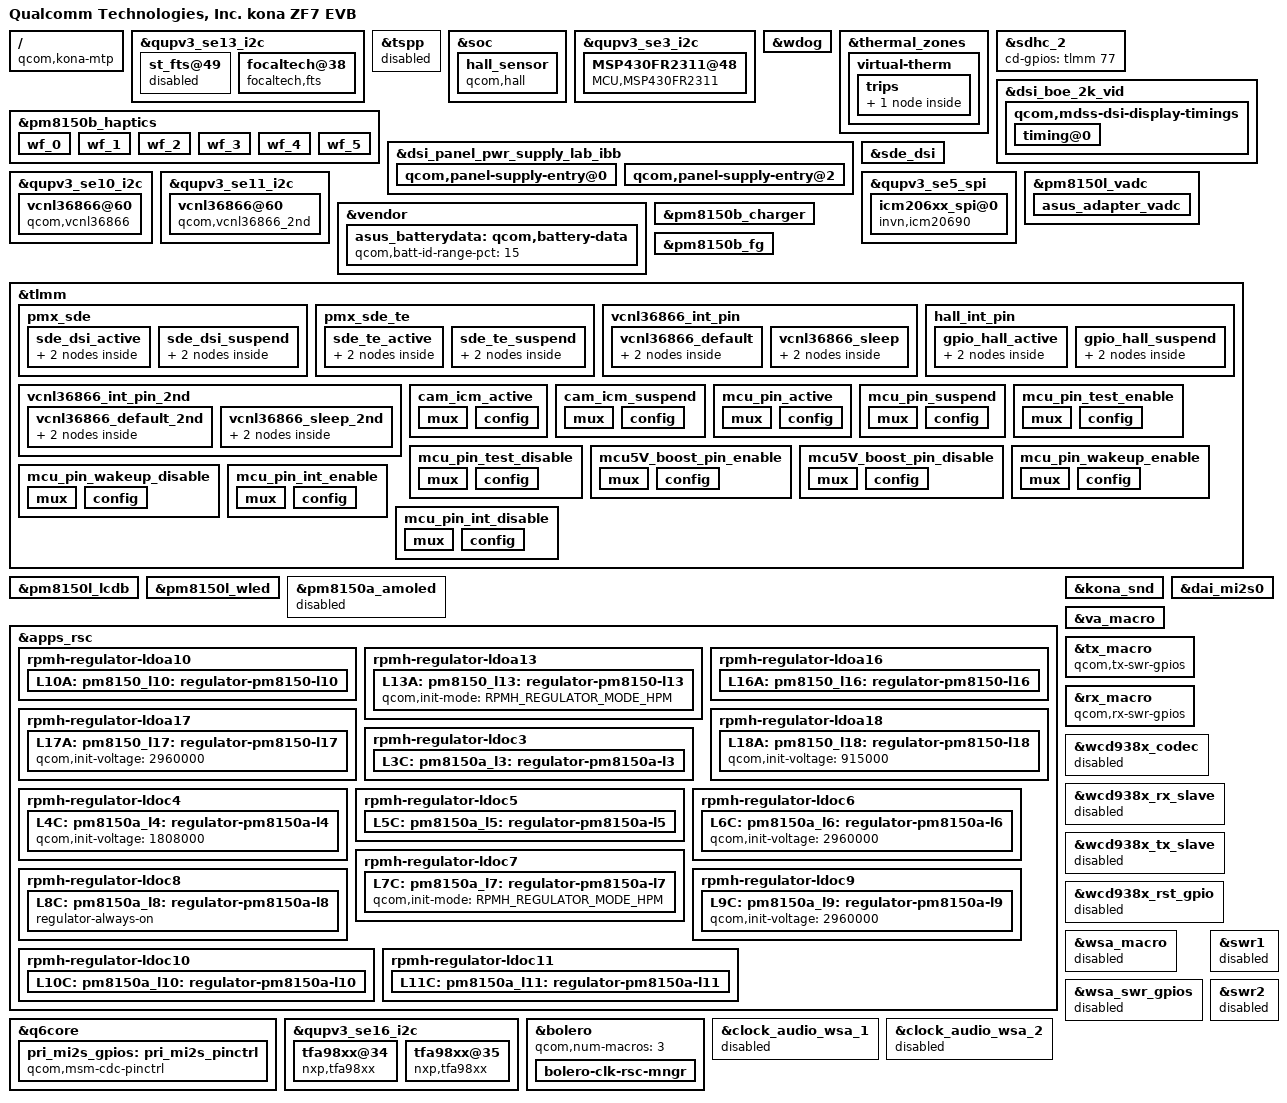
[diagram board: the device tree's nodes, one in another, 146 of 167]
/dts-v1/;
/plugin/;

#include <dt-bindings/clock/qcom,gcc-kona.h>
#include <dt-bindings/clock/qcom,camcc-kona.h>
#include <dt-bindings/clock/qcom,rpmh.h>
#include <dt-bindings/interrupt-controller/arm-gic.h>
#include <dt-bindings/regulator/qcom,rpmh-regulator-levels.h>

#include "kona-mtp.dtsi"
 #include "camera/zs670ks-evb-camera-sensor-mtp.dtsi"
// ZS670KS_Display_Lotta_Lu +++++++++ 
#include "dsi-panel-boe-2k-video.dtsi"
//ZS670KS_Display_Lotta_Lu --------

// ZS670KS_fingerprint;asus_bsp++
#include "zs670ks-goodix-fp.dtsi"
//ZS670KS_fingerprint;asus_bsp--

/ {
	model = "Qualcomm Technologies, Inc. kona ZF7 EVB";
	compatible = "qcom,kona-mtp", "qcom,kona", "qcom,mtp";
	qcom,board-id = <30 0>;
};




/*    ====================================
 *    overlay for kona-v2.dtsi - start
 *    ====================================
 */

/*    ====================================
 *    overlay for kona-v2.dtsi - end
 *    ====================================
 */



/*    ====================================
 *    overlay for kona.dtsi - start
 *    ====================================
 */
// ZS670KS touch Yadong +++
&qupv3_se13_i2c {
	status = "ok";
	/delete-property/ qcom,i2c-touch-active;

	st_fts@49 {
		status = "disable";
	};

	focaltech@38 {
		compatible = "focaltech,fts";
		reg = <0x38>;
		interrupt-parent = <&tlmm>;
		interrupts = <68 0x2008>;
		focaltech,reset-gpio = <&tlmm 69 0x01>;
		focaltech,irq-gpio = <&tlmm 68 0x2008>;
		focaltech,max-touch-number = <10>;
		vdd-supply = <&pm8150_l14>;
		lab-supply = <&lcdb_ldo_vreg>;
		ibb-supply = <&lcdb_ncp_vreg>;
		focaltech,regulator_dvdd = "vdd";
		focaltech,regulator_lab = "lab";
		focaltech,regulator_ibb = "ibb";
		focaltech,display-coords = <0 0 1080 2340>;
	};
};

&tspp {
	status = "disable";
};
// ZS670KS touch Yadong ---

//ZS670KS_HALL_sensor_Timo_Xu ++++++++++
&soc {
	
	hall_sensor {
		compatible = "qcom,hall";
		pinctrl-names = "hall_gpio_high","hall_gpio_low";
		pinctrl-0 = <&gpio_hall_active>;
		pinctrl-1 = <&gpio_hall_suspend>;			
		qcom,hall-gpio = <&tlmm 121 0x0>;
	};
};
//ZS670KS_HALL_sensor_Timo_Xu --------

//ZS670KS Camera moto, start.
&qupv3_se3_i2c {
        status = "ok";
        MSP430FR2311@48 {
			compatible = "MCU,MSP430FR2311";
			reg = <0x48>;
			vcc_s4a_1p8-supply = <&pm8150_s4>;
			vcc_l10a_3p3-supply = <&pm8150_l10>;
			pinctrl-names = "mcu_active", "mcu_suspend";
			pinctrl-0 = <&mcu_pin_active &mcu_pin_test_enable &mcu5V_boost_pin_enable &mcu_pin_wakeup_enable &mcu_pin_int_enable>;
			pinctrl-1 = <&mcu_pin_suspend &mcu_pin_test_disable &mcu5V_boost_pin_disable &mcu_pin_wakeup_disable &mcu_pin_int_disable>;
			gpios = <&tlmm 112 0>,<&tlmm 113 0>, <&tlmm 62 0>, <&tlmm 114 0> , <&tlmm 162 0>;

			MCU,mcureset-gpios = <&tlmm 112 0x00>;
			MCU,mcutest-gpios = <&tlmm 113 0x00>;
			MCU,mcu5V_boost_enable-gpios = <&tlmm 62 0x00>;
			MCU,mcuwakeup-gpios = <&tlmm 114 0x00>;
			MCU,mcuint-gpios = <&tlmm 162 0x00>;
			MCU,slave_address = <0x48>;
        };
};
//ZS670KS Camera moto, end.

//ZS670KS Watchdog ++++
&wdog {
	qcom,bark-time = <15000>;
	qcom,pet-time = <9360>;
};
//ZS670KS Watchdog ++

 /*    ====================================
 *    overlay for kona.dtsi - end
 *    ====================================
 */


/*    ====================================
 *    overlay for kona-mtp.dtsi - start
 *    ====================================
 */
 
 &thermal_zones { 	
	virtual-therm {
		polling-delay-passive = <0>;
		polling-delay = <0>;
		thermal-governor = "user_space";
		thermal-sensors = <&pm8150l_adc_tm ADC_AMUX_THM2_PU2>;
		trips {
			active-config0 {
				temperature = <125000>;
				hysteresis = <1000>;
				type = "passive";
			};
		};
	};
};
 
// ZS670KS_Haptics_Ryan_Ren +++++++++
&pm8150b_haptics {
	qcom,vmax-mv = <2420>;
	qcom,play-rate-us = <4255>;
	qcom,wf-brake-pattern = [02 02 02 02];
	wf_0 {
		/* CLICK */
		qcom,effect-id = <0>;
		qcom,wf-vmax-mv = <3596>;
		qcom,wf-pattern = [3e 3e 3e];
		qcom,wf-play-rate-us = <4255>;
		qcom,wf-brake-pattern = [02 02 00 00];
		/delete-property/ qcom,wf-repeat-count;
		/delete-property/ qcom,wf-s-repeat-count;
		/delete-property/ qcom,lra-auto-resonance-disable;
	};
	wf_1 {
		/* DOUBLE CLICK */
		qcom,effect-id = <1>;
		qcom,wf-vmax-mv = <2900>;
		qcom,wf-pattern = [7e 7e 02 02 02 02 02 02];
		qcom,wf-play-rate-us = <4166>;
		qcom,wf-repeat-count = <2>;
		qcom,wf-s-repeat-count = <1>;
		qcom,wf-brake-pattern = [02 02 00 00];
		/delete-property/ qcom,lra-auto-resonance-disable;
	}; 
	wf_2 {
		/* TICK */
		qcom,effect-id = <2>;
		qcom,wf-vmax-mv = <2900>;
		qcom,wf-pattern = [7e 7e];
		qcom,wf-play-rate-us = <4166>;
		qcom,wf-brake-pattern = [02 02 00 00];
		/delete-property/ qcom,wf-repeat-count;
		/delete-property/ qcom,wf-s-repeat-count;
		/delete-property/ qcom,lra-auto-resonance-disable;
	};
	wf_3 {
		/* THUD */
		qcom,effect-id = <3>;
		qcom,wf-vmax-mv = <2900>;
		qcom,wf-pattern = [7e 7e 7e];
		qcom,wf-play-rate-us = <4166>;
		qcom,wf-brake-pattern = [02 02 00 00];
		/delete-property/ qcom,wf-repeat-count;
		/delete-property/ qcom,wf-s-repeat-count;
		/delete-property/ qcom,lra-auto-resonance-disable;
	};
	wf_4 {
		/* POP */
		qcom,effect-id = <4>;
		qcom,wf-vmax-mv = <2900>;
		qcom,wf-pattern = [7e 7e];
		qcom,wf-play-rate-us = <4166>;
		qcom,wf-brake-pattern = [02 02 00 00];
		/delete-property/ qcom,wf-repeat-count;
		/delete-property/ qcom,wf-s-repeat-count;
		/delete-property/ qcom,lra-auto-resonance-disable;
	};
	wf_5 {
		/* HEAVY CLICK */
		qcom,effect-id = <5>;
		qcom,wf-vmax-mv = <2900>;
		qcom,wf-pattern = [7e 7e 7e];
		qcom,wf-play-rate-us = <4166>;
		qcom,wf-brake-pattern = [02 02 00 00];
		/delete-property/ qcom,wf-repeat-count;
		/delete-property/ qcom,wf-s-repeat-count;
		/delete-property/ qcom,lra-auto-resonance-disable;
	};
}; 
// ZS670KS_Haptics_Ryan_Ren ---------



//ZS670KS SDCARD Bevis ++++++++++++
&sdhc_2 {
	cd-gpios = <&tlmm 77 GPIO_ACTIVE_HIGH>;
	status = "ok";
};
//ZS670KS SDCARD Bevis ---------


// ZS670KS_Display_Lotta_Lu +++++++++ 
&dsi_panel_pwr_supply_lab_ibb {

	qcom,panel-supply-entry@0 {
		/delete-property/ qcom,supply-post-on-sleep;
	};

	qcom,panel-supply-entry@2 {
		/delete-property/ qcom,supply-post-on-sleep;
	};
};


&dsi_boe_2k_vid {

	qcom,panel-supply-entries = <&dsi_panel_pwr_supply_lab_ibb>;
	qcom,mdss-dsi-bl-pmic-control-type = "bl_ctrl_dcs";
	qcom,mdss-dsi-bl-min-level = <1>;
	qcom,mdss-dsi-bl-max-level = <4095>;
	qcom,mdss-dsi-mode-sel-gpio-state = "single_port";
	qcom,platform-te-gpio = <&tlmm 71 0>;
	qcom,platform-reset-gpio = <&tlmm 75 0>;

	qcom,mdss-dsi-display-timings {
		timing@0 {
			qcom,mdss-dsi-panel-phy-timings = [00 22 09 09 25 24 09
				09 06 02 04 00 1C 19];
			qcom,display-topology = <1 0 1>;
			qcom,default-topology-index = <0>;
		};
	};
};

&sde_dsi {
	/delete-property/ vdd-supply;
	/delete-property/ avdd-supply;

	lab-supply = <&lcdb_ldo_vreg>;
	ibb-supply = <&lcdb_ncp_vreg>;

	qcom,dsi-default-panel = <&dsi_boe_2k_vid>;
};
//ZS670KS_Display_Lotta_Lu --------

// ASUS_BSP +++ ClayWang vcnl36866 
&qupv3_se10_i2c {
        status = "ok";
            vcnl36866@60 {
			compatible = "qcom,vcnl36866";
			reg = <0x60>;
			pinctrl-names = "alsps_gpio_high","alsps_gpio_low";
			pinctrl-0 = <&vcnl36866_default>;
			pinctrl-1 = <&vcnl36866_sleep>;
			qcom,alsps-gpio = <&tlmm 126 0x0>;
			vcc_psensor-supply = <&pm8150a_l10>;
		};
};

&qupv3_se11_i2c {
        status = "ok";
            vcnl36866@60 {
			compatible = "qcom,vcnl36866_2nd";
			reg = <0x60>;
			pinctrl-names = "alsps_gpio_high_2nd","alsps_gpio_low_2nd";
			pinctrl-0 = <&vcnl36866_default_2nd>;
			pinctrl-1 = <&vcnl36866_sleep_2nd>;
			qcom,alsps-gpio_2nd = <&tlmm 67 0x0>;
			vcc_psensor-supply = <&pm8150a_l10>;
		};
};
// ASUS_BSP --- ClayWang vcnl36866

/* ASUS_BSP +++ icm20690 */
&qupv3_se5_spi {
	status = "ok";
        icm206xx_spi@0 {
                spi-max-frequency = <10000000>;
                compatible = "invn,icm20690";
                reg = <0x0>;
                invn,gpio-int = <&tlmm 124 1>;
                invn,use-interrupt;
                invn,place = "Portrait Down Back Side";
                icm206xx-supply = <&pm8150a_l1>;
                pinctrl-names = "cam_default", "cam_suspend";
                pinctrl-0 = <&cam_icm_active>;
                pinctrl-1 = <&cam_icm_suspend>;
        };
};
/* ASUS_BSP --- icm20690 */

/*    ====================================
 *    overlay for kona-mtp.dtsi - end
 *    ====================================
 */



// ASUS_BSP Fuel guage/Charger dtsi overlay +++
&vendor {
	asus_batterydata: qcom,battery-data {
		qcom,batt-id-range-pct = <15>;
		#include "fg-gen4-batterydata-mlp466076-3250mah.dtsi"
	};
};

&pm8150l_vadc {
	asus_adapter_vadc {
		reg = <ADC_GPIO4>;
		label = "asus_adapter_vadc";
		qcom,hw-settle-time = <200>;
		qcom,pre-scaling = <1 1>;
	};
};

&pm8150b_charger {
	io-channels = <&pm8150b_vadc ADC_MID_CHG_DIV6>,
		      <&pm8150b_vadc ADC_USB_IN_I>,
		      <&pm8150b_vadc ADC_SBUx>,
		      <&pm8150b_vadc ADC_VPH_PWR>,
		      <&pm8150b_vadc ADC_AMUX_THM3_PU2>,
		      <&pm8150b_vadc ADC_CHG_TEMP>,
		      <&pm8150l_vadc ADC_GPIO4>;
	io-channel-names = "mid_voltage",
			   "usb_in_current",
			   "sbux_res",
			   "vph_voltage",
			   "conn_temp",
			   "chg_temp",
			   "asus_adapter_vadc";
	ADCPWREN_PMI_GP1-gpio82 = <&pm8150b_gpios 3 0x0>; //EVB use PM8150B GPIO3, SR use SM8250 GPIO82
	ADC_SW_EN-gpio98 = <&tlmm 98 0x0>;
	qcom,battery-data = <&asus_batterydata>;
};

&pm8150b_fg {
	qcom,battery-data = <&asus_batterydata>;
	qcom,fg-cutoff-voltage = <3400>;
	qcom,fg-empty-voltage = <2650>;
	qcom,fg-cutoff-current = <100>;
	qcom,fg-force-load-profile;
};
// ASUS_BSP Fuel guage/Charger dtsi overlay ---

/*    ====================================
 *    overlay for kona-pinctrl.dtsi - start
 *    ====================================
 */
 
&tlmm{
// ZS670KS_Display_Lotta_Lu +++++++++ 

		pmx_sde: pmx_sde {
		
			sde_dsi_active: sde_dsi_active {
				mux {
					pins = "gpio75";
					function = "gpio";
				};

				config {
					pins = "gpio75";
					drive-strength = <8>;   /* 8 mA */
					bias-disable = <0>;   /* no pull */
				};
			};

			sde_dsi_suspend: sde_dsi_suspend {
				mux {
					pins = "gpio75";
					function = "gpio";
				};

				config {
					pins = "gpio75";
					drive-strength = <2>;   /* 2 mA */
					bias-pull-down;         /* PULL DOWN */
				};
			};
		};

		pmx_sde_te {
			sde_te_active: sde_te_active {
				mux {
					pins = "gpio71";
					function = "mdp_vsync";
				};

				config {
					pins = "gpio71";
					drive-strength = <2>;   /* 2 mA */
					bias-pull-down;         /* PULL DOWN */
				};
			};

			sde_te_suspend: sde_te_suspend {
				mux {
					pins = "gpio71";
					function = "mdp_vsync";
				};

				config {
					pins = "gpio71";
					drive-strength = <2>;   /* 2 mA */
					bias-pull-down;         /* PULL DOWN */
				};
			};
		};
//ZS670KS_Display_Lotta_Lu --------
		/* ASUS_BSP +++ ClayWang vcnl36866 */
		vcnl36866_int_pin {
			vcnl36866_default: vcnl36866_default {
				mux {
					pins = "gpio126";
					function = "gpio";
				};

				config {
					pins = "gpio126";
					bias-pull-up;
					drive-strength = <6>;
				};
			};

			vcnl36866_sleep: vcnl36866_sleep {
				mux {
					pins = "gpio126";
					function = "gpio";
				};

				config {
					pins = "gpio126";
					bias-pull-up;
					drive-strength = <6>;
				};
			};
		};
		vcnl36866_int_pin_2nd {
			vcnl36866_default_2nd: vcnl36866_default_2nd {
				mux {
					pins = "gpio67";
					function = "gpio";
				};

				config {
					pins = "gpio67";
					bias-pull-up;
					drive-strength = <6>;
				};
			};

			vcnl36866_sleep_2nd: vcnl36866_sleep_2nd {
				mux {
					pins = "gpio67";
					function = "gpio";
				};

				config {
					pins = "gpio67";
					bias-pull-up;
					drive-strength = <6>;
				};
			};
		};
		/* ASUS_BSP --- ClayWang vncl36866 */

//ZS670KS_HALL_sensor_Timo_Xu ++++++++
		hall_int_pin {

			gpio_hall_active: gpio_hall_active {
 				mux {
 					pins = "gpio121";
 					function = "gpio";
				};
 
 				config {
 					pins = "gpio121";
 					drive-strength = <2>;
 					bias-disable;
 				};
 			};
 			gpio_hall_suspend: gpio_hall_suspend {
 				mux {
 					pins = "gpio121";
 					function = "gpio";
 				};
 
 				config {
 					pins = "gpio121";
 					drive-strength = <2>;
 					bias-disable;
 				};
 			};
		};
//ZS670KS_HALL_sensor_Timo_Xu --------
		/* ASUS_BSP +++ icm20690 */
		cam_icm_active: cam_icm_active {
			mux {
				pins = "gpio124";
				function = "gpio";
			};

			config {
				pins = "gpio124";
				bias-pull-up;
				drive-strength = <8>;
			};
		};

		cam_icm_suspend: cam_icm_suspend {
			mux {
				pins = "gpio124";
				function = "gpio";
			};

			config {
				pins = "gpio124";
				bias-pull-down;
				drive-strength = <2>; 
			};
		};
		/* ASUS_BSP --- icm20690 */
//ZS670KS, camera moto related gpio, start.
mcu_pin_active: mcu_pin_active {
	mux {
		pins = "gpio112";
		function = "gpio";
	};

	config {
		pins = "gpio112";
		bias-pull-up; /* PULL UP */
		drive-strength = <2>; /* 2 MA */
	};
};

mcu_pin_suspend: mcu_pin_suspend {
	mux {
		pins = "gpio112";
		function = "gpio";
	};

	config {
		pins = "gpio112";
		bias-pull-up; /* PULL UP */
		drive-strength = <2>; /* 2 MA */
	};
};

mcu_pin_test_enable: mcu_pin_test_enable {
	mux {
		pins = "gpio113";
		function = "gpio";
	};

	config {
		pins = "gpio113";
		bias-pull-down; /* PULL UP */
		drive-strength = <2>; /* 2 MA */
	};
};

mcu_pin_test_disable: mcu_pin_test_disable {
	mux {
		pins = "gpio113";
		function = "gpio";
	};

	config {
		pins = "gpio113";
		bias-pull-down; /* PULL UP */
		drive-strength = <2>; /* 2 MA */
	};
};

mcu5V_boost_pin_enable: mcu5V_boost_pin_enable {
	mux {
		pins = "gpio62";
		function = "gpio";
	};

	config {
		pins = "gpio62";
		bias-pull-up; 
		drive-strength = <2>; /* 2 MA */
	};
};

mcu5V_boost_pin_disable: mcu5V_boost_pin_disable {
	mux {
		pins = "gpio62";
		function = "gpio";
	};

	config {
		pins = "gpio62";
		bias-pull-down; 
		drive-strength = <2>; /* 2 MA */
	};
};

mcu_pin_wakeup_enable: mcu_pin_wakeup_enable {
	mux {
		pins = "gpio114";
		function = "gpio";
	};

	config {
		pins = "gpio114";
		bias-pull-up; 
		drive-strength = <2>; /* 2 MA */
	};
};

mcu_pin_wakeup_disable: mcu_pin_wakeup_disable {
	mux {
		pins = "gpio114";
		function = "gpio";
	};

	config {
		pins = "gpio114";
		bias-pull-down; 
		drive-strength = <2>; /* 2 MA */
	};
};

mcu_pin_int_enable: mcu_pin_int_enable {
	mux {
		pins = "gpio162";
		function = "gpio";
	};

	config {
		pins = "gpio162";
		bias-pull-up; 
		drive-strength = <2>; /* 2 MA */
	};
};

mcu_pin_int_disable: mcu_pin_int_disable {
	mux {
		pins = "gpio162";
		function = "gpio";
	};

	config {
		pins = "gpio162";
		bias-pull-down; 
		drive-strength = <2>; /* 2 MA */
	};
};	
//ZS670KS, camera moto related gpio, end.

};

/*    ====================================
 *    overlay for kona-pinctrl.dtsi - end
 *    ====================================
 */



/*    ====================================
 *    overlay for kona-pmic-overlay.dtsi  - start
 *    ====================================
 */

// ZS670KS_Display_Lotta_Lu +++++++++ 
&pm8150l_lcdb {
	status = "ok";
};

&pm8150l_wled {
	status = "ok";
	qcom,en-cabc;
	qcom,cabc-sel = <1>;
	qcom,fs-current = <9>; //8 = 20mA, 9 = 22.5mA, max is 12, min is 0
	qcom,string-cfg= <3>;
	qcom,leds-per-string = <8>;
};

&pm8150a_amoled{
	status = "disabled";
};
//ZS670KS_Display_Lotta_Lu --------
/*    ====================================
 *    overlay for kona-pmic-overlay.dtsi - end
 *    ====================================
 */



/*    ====================================
 *    overlay for kona-regulator.dtsi - start
 *    ====================================
 */
 
// ASUS_BSP +++ ClayWang vcnl36866 
&apps_rsc {

	rpmh-regulator-ldoa10 {
			L10A: pm8150_l10: regulator-pm8150-l10 {
				regulator-max-microvolt = <3300000>;
				qcom,init-voltage = <3300000>;
			};
	};

	rpmh-regulator-ldoa13 {
		L13A: pm8150_l13: regulator-pm8150-l13 {
			qcom,init-mode = <RPMH_REGULATOR_MODE_HPM>;
		};
	};

	rpmh-regulator-ldoa16 {
		L16A: pm8150_l16: regulator-pm8150-l16 {
			regulator-min-microvolt = <2850000>;
			qcom,init-voltage = <2850000>;
		};
	};

	rpmh-regulator-ldoa17 {
		L17A: pm8150_l17: regulator-pm8150-l17 {
			qcom,init-voltage = <2960000>;
		};
	};

	rpmh-regulator-ldoa18 {
		L18A: pm8150_l18: regulator-pm8150-l18 {
			qcom,init-voltage = <915000>;
		};
	};

	rpmh-regulator-ldoc3 {
		L3C: pm8150a_l3: regulator-pm8150a-l3 {
			qcom,init-voltage = <1200000>;
			qcom,init-mode = <RPMH_REGULATOR_MODE_HPM>;
		};
	};

	rpmh-regulator-ldoc4 {
		L4C: pm8150a_l4: regulator-pm8150a-l4 {
			qcom,init-voltage = <1808000>;
		};
	};

	rpmh-regulator-ldoc5 {
		L5C: pm8150a_l5: regulator-pm8150a-l5 {
			qcom,init-voltage = <1808000>;
			qcom,init-mode = <RPMH_REGULATOR_MODE_HPM>;
		};
	};

	rpmh-regulator-ldoc6 {
		L6C: pm8150a_l6: regulator-pm8150a-l6 {
			qcom,init-voltage = <2960000>;
		};
	};

	rpmh-regulator-ldoc7 {
		L7C: pm8150a_l7: regulator-pm8150a-l7 {
			qcom,init-mode = <RPMH_REGULATOR_MODE_HPM>;
		};
	};

	rpmh-regulator-ldoc8 {
		/*
		qcom,supported-modes =
			<RPMH_REGULATOR_MODE_LPM
			 RPMH_REGULATOR_MODE_HPM>;
		*/
		L8C: pm8150a_l8: regulator-pm8150a-l8 {
			//qcom,init-mode = <RPMH_REGULATOR_MODE_HPM>;
			regulator-always-on;	/* ASUS BSP Always Enable 1.8V for I2C & Sensors */
		};
	};

	rpmh-regulator-ldoc9 {
		L9C: pm8150a_l9: regulator-pm8150a-l9 {
			qcom,init-voltage = <2960000>;
		};
	};

	rpmh-regulator-ldoc10 {
		L10C: pm8150a_l10: regulator-pm8150a-l10 {
			regulator-min-microvolt = <3000000>;
			regulator-max-microvolt = <3000000>;
			qcom,init-mode = <RPMH_REGULATOR_MODE_HPM>;
			regulator-always-on;	/* ASUS BSP Always Enable 1.8V for I2C & Sensors */
		};
	};

	rpmh-regulator-ldoc11 {
		L11C: pm8150a_l11: regulator-pm8150a-l11 {
			qcom,init-voltage = <3300000>;
			qcom,init-mode = <RPMH_REGULATOR_MODE_HPM>;
		};
	};

};
// ASUS_BSP --- ClayWang vcnl36866 

/*    ====================================
 *    overlay for kona-regulator.dtsi - end
 *    ====================================
 */
 


/*    ====================================
 *    overlay for kona-audio-overlay.dtsi - start
 *    ====================================
 */
&kona_snd {
	qcom,model = "kona-mtp-snd-card";
	qcom,msm-mi2s-master = <1>, <1>, <1>, <1>, <1>, <1>;
	qcom,wcn-bt = <1>;
	qcom,ext-disp-audio-rx = <1>;
    qcom,mi2s-audio-intf = <1>;
    qcom,pri-mi2s-gpios = <&pri_mi2s_gpios>;
	qcom,audio-routing =
		"RX_TX DEC0_INP", "TX DEC0 MUX",
		"RX_TX DEC1_INP", "TX DEC1 MUX",
		"RX_TX DEC2_INP", "TX DEC2 MUX",
		"RX_TX DEC3_INP", "TX DEC3 MUX",
		"VA_AIF1 CAP", "VA_SWR_CLK",
		"VA_AIF2 CAP", "VA_SWR_CLK",
		"VA_AIF3 CAP", "VA_SWR_CLK",
		"VA MIC BIAS", "Digital Mic0",
		"VA MIC BIAS", "Digital Mic1",
		"VA MIC BIAS", "Digital Mic2",
		"VA MIC BIAS", "Digital Mic3",
		"VA MIC BIAS", "Digital Mic4",
		"VA MIC BIAS", "Digital Mic5",
		"VA DMIC0", "VA MIC BIAS",
		"VA DMIC1", "VA MIC BIAS",
		"VA DMIC2", "VA MIC BIAS",
		"VA DMIC3", "VA MIC BIAS",
		"VA DMIC4", "VA MIC BIAS",
		"VA DMIC5", "VA MIC BIAS";
	qcom,msm-mbhc-hphl-swh;
	qcom,msm-mbhc-gnd-swh;
	qcom,cdc-dmic01-gpios = <&cdc_dmic01_gpios>;
	qcom,cdc-dmic23-gpios = <&cdc_dmic23_gpios>;
	qcom,cdc-dmic45-gpios = <&cdc_dmic45_gpios>;
	asoc-codec  = <&stub_codec>, <&bolero>, <&ext_disp_audio_codec>;
	asoc-codec-names = "msm-stub-codec.1", "bolero_codec",
			   "msm-ext-disp-audio-codec-rx";
	qcom,wsa-max-devs = <0>;
	qcom,wsa-devs;
	qcom,wsa-aux-dev-prefix;
	qcom,codec-max-aux-devs = <0>;
	qcom,codec-aux-devs;
	qcom,msm_audio_ssr_devs = <&audio_apr>, <&q6core>, <&lpi_tlmm>,
				  <&bolero>;
};

&q6core {
    pri_mi2s_gpios: pri_mi2s_pinctrl {
        compatible = "qcom,msm-cdc-pinctrl";
		pinctrl-names = "aud_active", "aud_sleep";
		pinctrl-0 = <&pri_aux_pcm_clk_active &pri_aux_pcm_din_active &pri_aux_pcm_dout_active &pri_aux_pcm_sync_active>;
		pinctrl-1 = <&pri_aux_pcm_clk_sleep &pri_aux_pcm_din_sleep &pri_aux_pcm_dout_sleep &pri_aux_pcm_sync_sleep>;
    };
};

&qupv3_se16_i2c {
       status = "ok";
	tfa98xx@34 {
		compatible = "nxp,tfa98xx";
		reg = <0x34>;
		reset-gpio = <&tlmm 72 0>;
		irq-gpio = <&tlmm 64 0>;
	};
	tfa98xx@35 {
		compatible = "nxp,tfa98xx";
		reg = <0x35>;
		reset-gpio = <&tlmm 73 0>;
		irq-gpio = <&tlmm 63 0>;
        };
};

&dai_mi2s0 {
    qcom,msm-mi2s-rx-lines = <2>;
    qcom,msm-mi2s-tx-lines = <1>;
};

&va_macro {
	va-vdd-micb-supply = <&L4C>;
	qcom,va-dmic-sample-rate = <2400000>;
};

&tx_macro {
    qcom,tx-swr-gpios;
};

&rx_macro {
    qcom,rx-swr-gpios;
};

&wcd938x_codec {
	status = "disabled";
};

&wcd938x_rx_slave {
	status = "disabled";
};

&wcd938x_tx_slave {
	status = "disabled";
};

&wcd938x_rst_gpio {
	status = "disabled";
};

&wsa_macro {
	status = "disabled";
};

&wsa_swr_gpios {
	status = "disabled";
};

&swr1 {
    status = "disabled";
};

&swr2 {
    status = "disabled";
};

&bolero {
	qcom,num-macros = <3>;
	bolero-clk-rsc-mngr {
		clock-names = "tx_core_clk", "tx_npl_clk", "rx_core_clk", "rx_npl_clk",
			 "va_core_clk", "va_npl_clk";
		clocks = <&clock_audio_tx_1 0>, <&clock_audio_tx_2 0>,
			<&clock_audio_rx_1 0>, <&clock_audio_rx_2 0>,
			<&clock_audio_va_1 0>, <&clock_audio_va_2 0>;
	};
};

&clock_audio_wsa_1 {
	status = "disabled";
};

&clock_audio_wsa_2 {
	status = "disabled";
};

/*    ====================================
 *    overlay for kona-audio-overlay.dtsi - end
 *    ====================================
 */




/*    ====================================
 *    overlay for kona-camera-sensor-mtp.dtsi - start
 *    ====================================
 */

/*    ====================================
 *    overlay for kona-camera-sensor-mtp.dtsi - end
 *    ====================================
 */
